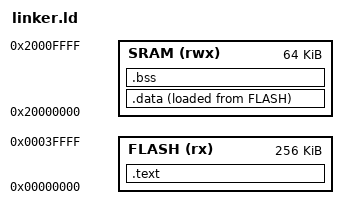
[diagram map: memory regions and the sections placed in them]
/*
 * SPDX-License-Identifier: GPL-3.0-only
 */

MEMORY
{
    FLASH (rx)  : ORIGIN = 0x00000000, LENGTH = 256K
    SRAM  (rwx) : ORIGIN = 0x20000000, LENGTH = 64K
}

ENTRY(Reset_Handler)

SECTIONS
{
    .text :
    {
        KEEP(*(.isr_vector))
        *(.text*)
        *(.rodata*)
        . = ALIGN(4);
    } > FLASH

    _sidata = LOADADDR(.data);

    .data :
    {
        _sdata = .;
        *(.data*)
        . = ALIGN(4);
        _edata = .;
    } > SRAM AT> FLASH

    .bss :
    {
        _sbss = .;
        *(.bss*)
        *(COMMON)
        . = ALIGN(4);
        _ebss = .;
    } > SRAM

    _estack = ORIGIN(SRAM) + LENGTH(SRAM);
}
